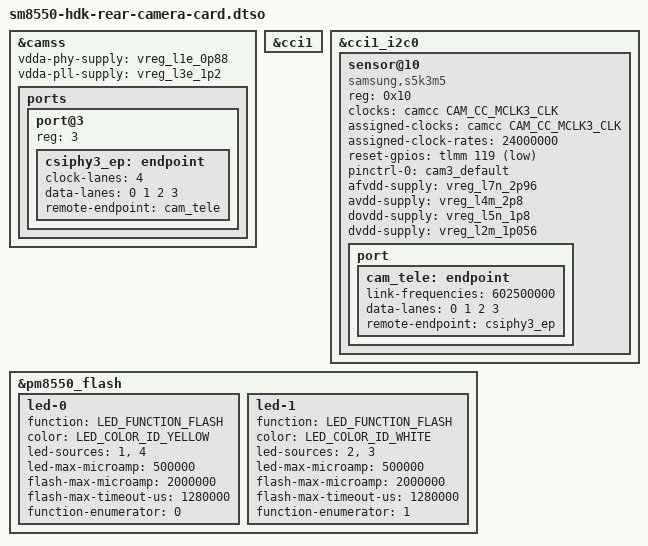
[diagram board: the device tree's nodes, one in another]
// SPDX-License-Identifier: BSD-3-Clause
/*
 * SM8550-HDK Rear Camera Card overlay
 *
 * Copyright (c) 2025, Linaro Limited
 */

#include <dt-bindings/clock/qcom,sm8550-camcc.h>
#include <dt-bindings/gpio/gpio.h>
#include <dt-bindings/leds/common.h>

/dts-v1/;
/plugin/;

&camss {
	status = "okay";

	vdda-phy-supply = <&vreg_l1e_0p88>;
	vdda-pll-supply = <&vreg_l3e_1p2>;

	ports {
		#address-cells = <1>;
		#size-cells = <0>;

		port@3 {
			reg = <3>;

			csiphy3_ep: endpoint {
				clock-lanes = <4>;
				data-lanes = <0 1 2 3>;
				remote-endpoint = <&cam_tele>;
			};
		};
	};
};

&cci1 {
	status = "okay";
};

&cci1_i2c0 {
	#address-cells = <1>;
	#size-cells = <0>;

	sensor@10 {
		compatible = "samsung,s5k3m5";
		reg = <0x10>;
		clocks = <&camcc CAM_CC_MCLK3_CLK>;
		assigned-clocks = <&camcc CAM_CC_MCLK3_CLK>;
		assigned-clock-rates = <24000000>;
		reset-gpios = <&tlmm 119 GPIO_ACTIVE_LOW>;
		pinctrl-0 = <&cam3_default>;
		pinctrl-names = "default";
		afvdd-supply = <&vreg_l7n_2p96>;
		avdd-supply = <&vreg_l4m_2p8>;
		dovdd-supply = <&vreg_l5n_1p8>;
		dvdd-supply = <&vreg_l2m_1p056>;

		port {
			cam_tele: endpoint {
				link-frequencies = /bits/ 64 <602500000>;
				data-lanes = <0 1 2 3>;
				remote-endpoint = <&csiphy3_ep>;
			};
		};
	};
};

&pm8550_flash {
	status = "okay";

	led-0 {
		function = LED_FUNCTION_FLASH;
		color = <LED_COLOR_ID_YELLOW>;
		led-sources = <1>, <4>;
		led-max-microamp = <500000>;
		flash-max-microamp = <2000000>;
		flash-max-timeout-us = <1280000>;
		function-enumerator = <0>;
	};

	led-1 {
		function = LED_FUNCTION_FLASH;
		color = <LED_COLOR_ID_WHITE>;
		led-sources = <2>, <3>;
		led-max-microamp = <500000>;
		flash-max-microamp = <2000000>;
		flash-max-timeout-us = <1280000>;
		function-enumerator = <1>;
	};
};
